AUTOSAR XML (schema 4-2-2)
package /STELLANTIS/EPT/COMSWCs
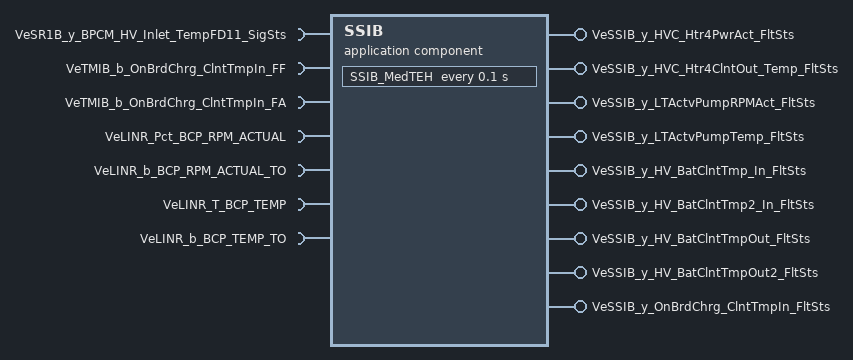
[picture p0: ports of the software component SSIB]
  application sw component type SSIB
    7 x require port:
      VeSR1B_y_BPCM_HV_Inlet_TempFD11_SigSts: variation-point={short-label=vpVeSR1B_y_BPCM_HV_Inlet_TempFD11_SigSts, sw-syscond=1}, nonqueued-receiver-com-spec{data-element=Value, init-value=0}, required-interface=VeSR1B_y_BPCM_HV_Inlet_TempFD11_SigSts
      VeTMIB_b_OnBrdChrg_ClntTmpIn_FF: variation-point={short-label=vpVeTMIB_b_OnBrdChrg_ClntTmpIn_FF, sw-syscond=1}, nonqueued-receiver-com-spec{data-element=Value, init-value=0}, required-interface=VeTMIB_b_OnBrdChrg_ClntTmpIn_FF
      VeTMIB_b_OnBrdChrg_ClntTmpIn_FA: variation-point={short-label=vpVeTMIB_b_OnBrdChrg_ClntTmpIn_FA, sw-syscond=1}, nonqueued-receiver-com-spec{data-element=Value, init-value=0}, required-interface=VeTMIB_b_OnBrdChrg_ClntTmpIn_FA
      VeLINR_Pct_BCP_RPM_ACTUAL: variation-point={short-label=vpVeLINR_Pct_BCP_RPM_ACTUAL, sw-syscond=1}, nonqueued-receiver-com-spec{data-element=VeLINR_Pct_BCP_RPM_ACTUAL, handle-never-received=true, init-value=0}, required-interface=VeLINR_Pct_BCP_RPM_ACTUAL
      VeLINR_b_BCP_RPM_ACTUAL_TO: variation-point={short-label=vpVeLINR_b_BCP_RPM_ACTUAL_TO, sw-syscond=1}, nonqueued-receiver-com-spec{data-element=VeLINR_b_BCP_RPM_ACTUAL_TO, init-value=0}, required-interface=VeLINR_b_BCP_RPM_ACTUAL_TO
      VeLINR_T_BCP_TEMP: variation-point={short-label=vpVeLINR_T_BCP_TEMP, sw-syscond=1}, nonqueued-receiver-com-spec{data-element=VeLINR_T_BCP_TEMP, handle-never-received=true, init-value=0}, required-interface=VeLINR_T_BCP_TEMP
      VeLINR_b_BCP_TEMP_TO: variation-point={short-label=vpVeLINR_b_BCP_TEMP_TO, sw-syscond=1}, nonqueued-receiver-com-spec{data-element=VeLINR_b_BCP_TEMP_TO, init-value=0}, required-interface=VeLINR_b_BCP_TEMP_TO
    9 x provide port, all with nonqueued-sender-com-spec{data-element=Value, init-value=0}:
      VeSSIB_y_HVC_Htr4PwrAct_FltSts: provided-interface=VeSSIB_y_HVC_Htr4PwrAct_FltSts
      VeSSIB_y_HVC_Htr4ClntOut_Temp_FltSts: provided-interface=VeSSIB_y_HVC_Htr4ClntOut_Temp_FltSts
      VeSSIB_y_LTActvPumpRPMAct_FltSts: provided-interface=VeSSIB_y_LTActvPumpRPMAct_FltSts
      VeSSIB_y_LTActvPumpTemp_FltSts: provided-interface=VeSSIB_y_LTActvPumpTemp_FltSts
      VeSSIB_y_HV_BatClntTmp_In_FltSts: provided-interface=VeSSIB_y_HV_BatClntTmp_In_FltSts
      VeSSIB_y_HV_BatClntTmp2_In_FltSts: provided-interface=VeSSIB_y_HV_BatClntTmp2_In_FltSts
      VeSSIB_y_HV_BatClntTmpOut_FltSts: provided-interface=VeSSIB_y_HV_BatClntTmpOut_FltSts
      VeSSIB_y_HV_BatClntTmpOut2_FltSts: provided-interface=VeSSIB_y_HV_BatClntTmpOut2_FltSts
      VeSSIB_y_OnBrdChrg_ClntTmpIn_FltSts: provided-interface=VeSSIB_y_OnBrdChrg_ClntTmpIn_FltSts
    behavior IB_SSIB: data-type-mapping=[msADTtoIDTMapping, ADTtoIDTMapping], handle-termination-and-restart=NO-SUPPORT
      timing event Event_MedTEH: start-on-event=SSIB_MedTEH, period=0.1
      init event Event_SSIB_ac_Init: start-on-event=SSIB_ac_Init
      data received event Event_SSIBDRE_BCP_STAT: start-on-event=SSIB_BCP_STAT_Received, data=VeLINR_b_BCP_RPM_ACTUAL_TO.VeLINR_b_BCP_RPM_ACTUAL_TO
      data received event Event_SSIBDRE_BATTERY_HV_STATUS1: start-on-event=SSIB_BATTERY_HV_STATUS1_Received, data=VeSR1B_y_BPCM_HV_Inlet_TempFD11_SigSts.Value
      4 x runnable:
        SSIB_ac_Init
        SSIB_MedTEH
          data-receive-point-by-arguments:
            access IN_VeTMIB_b_OnBrdChrg_ClntTmpIn_FA_Value: accessed-variable=VeTMIB_b_OnBrdChrg_ClntTmpIn_FA.Value, variation-point={short-label=vpIN_VeTMIB_b_OnBrdChrg_ClntTmpIn_FA_Value, sw-syscond=1}
            access IN_VeTMIB_b_OnBrdChrg_ClntTmpIn_FF_Value: accessed-variable=VeTMIB_b_OnBrdChrg_ClntTmpIn_FF.Value, variation-point={short-label=vpIN_VeTMIB_b_OnBrdChrg_ClntTmpIn_FF_Value, sw-syscond=1}
          data-send-points:
            access OUT_VeSSIB_y_OnBrdChrg_ClntTmpIn_FltSts_Value: accessed-variable=VeSSIB_y_OnBrdChrg_ClntTmpIn_FltSts.Value
        SSIB_BCP_STAT_Received
          data-receive-point-by-arguments:
            4 x access:
              IN_VeLINR_b_BCP_RPM_ACTUAL_TO_VeLINR_b_BCP_RPM_ACTUAL_TO: accessed-variable=VeLINR_b_BCP_RPM_ACTUAL_TO.VeLINR_b_BCP_RPM_ACTUAL_TO, variation-point={short-label=vpIN_VeLINR_b_BCP_RPM_ACTUAL_TO_VeLINR_b_BCP_RPM_ACTUAL_TO, sw-syscond=1}
              IN_VeLINR_b_BCP_TEMP_TO_VeLINR_b_BCP_TEMP_TO: accessed-variable=VeLINR_b_BCP_TEMP_TO.VeLINR_b_BCP_TEMP_TO, variation-point={short-label=vpIN_VeLINR_b_BCP_TEMP_TO_VeLINR_b_BCP_TEMP_TO, sw-syscond=1}
              IN_VeLINR_Pct_BCP_RPM_ACTUAL_VeLINR_Pct_BCP_RPM_ACTUAL: accessed-variable=VeLINR_Pct_BCP_RPM_ACTUAL.VeLINR_Pct_BCP_RPM_ACTUAL, variation-point={short-label=vpIN_VeLINR_Pct_BCP_RPM_ACTUAL_VeLINR_Pct_BCP_RPM_ACTUAL, sw-syscond=1}
              IN_VeLINR_T_BCP_TEMP_VeLINR_T_BCP_TEMP: accessed-variable=VeLINR_T_BCP_TEMP.VeLINR_T_BCP_TEMP, variation-point={short-label=vpIN_VeLINR_T_BCP_TEMP_VeLINR_T_BCP_TEMP, sw-syscond=1}
          data-send-points:
            access OUT_VeSSIB_y_LTActvPumpRPMAct_FltSts_Value: accessed-variable=VeSSIB_y_LTActvPumpRPMAct_FltSts.Value
            access OUT_VeSSIB_y_LTActvPumpTemp_FltSts_Value: accessed-variable=VeSSIB_y_LTActvPumpTemp_FltSts.Value
        SSIB_BATTERY_HV_STATUS1_Received
          data-receive-point-by-arguments:
            access IN_VeSR1B_y_BPCM_HV_Inlet_TempFD11_SigSts_Value: accessed-variable=VeSR1B_y_BPCM_HV_Inlet_TempFD11_SigSts.Value, variation-point={short-label=vpIN_VeSR1B_y_BPCM_HV_Inlet_TempFD11_SigSts_Value, sw-syscond=1}
          data-send-points:
            access OUT_VeSSIB_y_HV_BatClntTmp_In_FltSts_Value: accessed-variable=VeSSIB_y_HV_BatClntTmp_In_FltSts.Value
      variation point proxy Variant_SSIB_BATTERY_HV_STATUS1_PRESENCE: category=CONDITION, condition-access=1
      variation point proxy Variant_SSIB_BCP_STAT_PRESENCE: category=CONDITION, condition-access=1
      variation point proxy Variant_SSIB_PECTOS_PRESENCE: category=CONDITION, condition-access=1
